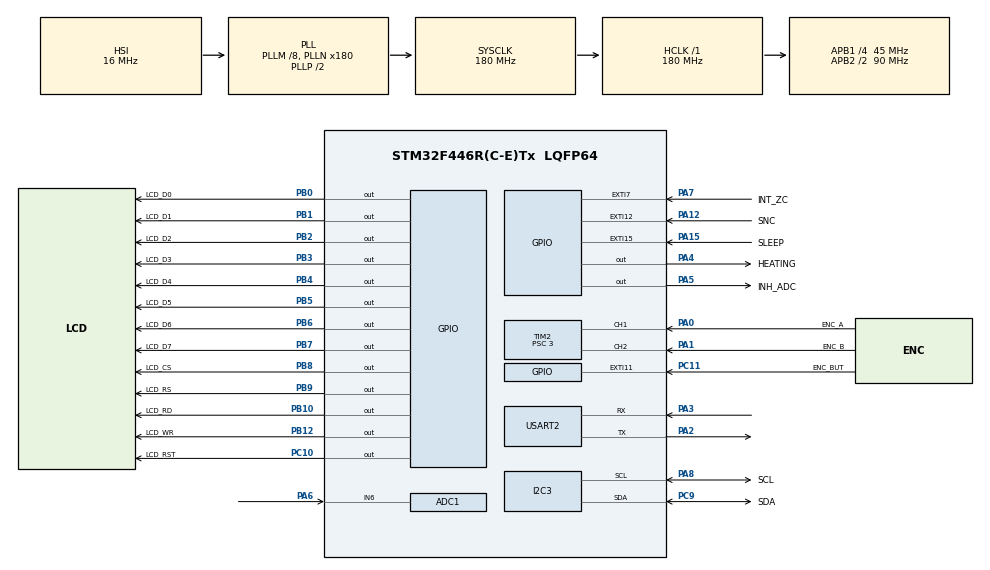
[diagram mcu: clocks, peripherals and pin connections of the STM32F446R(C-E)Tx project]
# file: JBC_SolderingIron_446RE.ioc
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ADC1.Channel-0\#ChannelRegularConversion=ADC_CHANNEL_6
ADC1.NbrOfConversionFlag=1
ADC1.Rank-0\#ChannelRegularConversion=1
ADC1.SamplingTime-0\#ChannelRegularConversion=ADC_SAMPLETIME_3CYCLES
ADC1.master=1
Mcu.Family=STM32F4
Mcu.Name=STM32F446R(C-E)Tx
Mcu.Package=LQFP64
NVIC.ADC_IRQn=true\:0\:0\:false\:false\:true\:true\:true
NVIC.EXTI15_10_IRQn=true\:0\:0\:false\:false\:true\:true\:true
NVIC.EXTI9_5_IRQn=true\:0\:0\:false\:false\:true\:true\:true
NVIC.I2C3_ER_IRQn=true\:0\:0\:false\:false\:true\:true\:true
NVIC.I2C3_EV_IRQn=true\:0\:0\:false\:false\:true\:true\:true
NVIC.PriorityGroup=NVIC_PRIORITYGROUP_4
NVIC.TIM2_IRQn=true\:0\:0\:false\:false\:true\:true\:true
NVIC.USART2_IRQn=true\:0\:0\:false\:false\:true\:true\:true
PA0-WKUP.GPIO_Label=ENC_A
PA0-WKUP.Signal=S_TIM2_CH1_ETR
PA1.GPIO_Label=ENC_B
PA1.Signal=S_TIM2_CH2
PA12.GPIO_Label=SNC
PA12.Signal=GPXTI12
PA13.GPIO_Label=SWDIO
PA13.Mode=Serial_Wire
PA13.Signal=SYS_JTMS-SWDIO
PA14.GPIO_Label=SWDCLK
PA14.Mode=Serial_Wire
PA14.Signal=SYS_JTCK-SWCLK
PA15.GPIO_Label=SLEEP
PA15.Signal=GPXTI15
PA2.Mode=Asynchronous
PA2.Signal=USART2_TX
PA3.Mode=Asynchronous
PA3.Signal=USART2_RX
PA4.GPIO_Label=HEATING
PA4.Signal=GPIO_Output
PA5.GPIO_Label=INH_ADC
PA5.Signal=GPIO_Output
PA6.Signal=ADCx_IN6
PA7.GPIO_Label=INT_ZC
PA7.Signal=GPXTI7
PA8.GPIO_Label=SCL
PA8.Mode=I2C
PA8.Signal=I2C3_SCL
PB0.GPIO_Label=LCD_D0
PB0.Signal=GPIO_Output
PB1.GPIO_Label=LCD_D1
PB1.Signal=GPIO_Output
PB10.GPIO_Label=LCD_RD
PB10.Signal=GPIO_Output
PB12.GPIO_Label=LCD_WR
PB12.Signal=GPIO_Output
PB2.GPIO_Label=LCD_D2
PB2.Signal=GPIO_Output
PB3.GPIO_Label=LCD_D3
PB3.Signal=GPIO_Output
PB4.GPIO_Label=LCD_D4
PB4.Signal=GPIO_Output
PB5.GPIO_Label=LCD_D5
PB5.Signal=GPIO_Output
PB6.GPIO_Label=LCD_D6
PB6.Signal=GPIO_Output
PB7.GPIO_Label=LCD_D7
PB7.Signal=GPIO_Output
PB8.GPIO_Label=LCD_CS
PB8.Signal=GPIO_Output
PB9.GPIO_Label=LCD_RS
PB9.Signal=GPIO_Output
PC10.GPIO_Label=LCD_RST
PC10.Signal=GPIO_Output
PC11.GPIO_Label=ENC_BUT
PC11.Signal=GPXTI11
PC9.GPIO_Label=SDA
PC9.Mode=I2C
PC9.Signal=I2C3_SDA
ProjectManager.HeapSize=0x200
ProjectManager.StackSize=0x400
ProjectManager.TargetToolchain=STM32CubeIDE
RCC.AHBFreq_Value=180000000
RCC.APB1CLKDivider=RCC_HCLK_DIV4
RCC.APB1Freq_Value=45000000
RCC.APB1TimFreq_Value=90000000
RCC.APB2CLKDivider=RCC_HCLK_DIV2
RCC.APB2Freq_Value=90000000
RCC.APB2TimFreq_Value=180000000
RCC.CortexFreq_Value=180000000
RCC.HCLKFreq_Value=180000000
RCC.PLLM=8
RCC.PLLN=180
RCC.SYSCLKFreq_VALUE=180000000
RCC.SYSCLKSource=RCC_SYSCLKSOURCE_PLLCLK
RCC.USBFreq_Value=180000000
RCC.VCOOutputFreq_Value=360000000
SH.ADCx_IN6.0=ADC1_IN6,IN6
SH.S_TIM2_CH1_ETR.0=TIM2_CH1,Encoder_Interface
SH.S_TIM2_CH2.0=TIM2_CH2,Encoder_Interface
TIM2.ClockDivision=TIM_CLOCKDIVISION_DIV4
TIM2.EncoderMode=TIM_ENCODERMODE_TI12
TIM2.IC1Filter=0xF
TIM2.IC1Polarity=TIM_ICPOLARITY_FALLING
TIM2.IC1Prescaler=TIM_ICPSC_DIV8
TIM2.IC2Filter=0xF
TIM2.IC2Polarity=TIM_ICPOLARITY_FALLING
TIM2.IC2Prescaler=TIM_ICPSC_DIV8
TIM2.Period=0xFFFF
TIM2.Prescaler=3
TIM2.TIM_MasterSlaveMode=TIM_MASTERSLAVEMODE_DISABLE
USART2.VirtualMode=VM_ASYNC
VP_CRC_VS_CRC.Mode=CRC_Activate
board=custom

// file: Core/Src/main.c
/* USER CODE BEGIN Header */
/**
  ******************************************************************************
  * @file           : main.c
  * @brief          : Main program body
  ******************************************************************************
  * @attention
  *
  * <h2><center>&copy; Copyright (c) 2019 STMicroelectronics.
  * All rights reserved.</center></h2>
  *
  * This software component is licensed by ST under BSD 3-Clause license,
  * the "License"; You may not use this file except in compliance with the
  * License. You may obtain a copy of the License at:
  *                        opensource.org/licenses/BSD-3-Clause
  *
  ******************************************************************************
  */
/* USER CODE END Header */

#include "main.h"
#include "adc.h"
#include "crc.h"
#include "i2c.h"
#include "tim.h"
#include "usart.h"
#include "gpio.h"

/* USER CODE BEGIN Includes */
#include "Application.h"
/* USER CODE END Includes */

void SystemClock_Config(void);

int main(void)
{

  /* MCU Configuration--------------------------------------------------------*/

  /* Reset of all peripherals, Initializes the Flash interface and the Systick. */
  HAL_Init();

  /* Configure the system clock */
  SystemClock_Config();

  /* Initialize all configured peripherals */
  MX_GPIO_Init();
  MX_ADC1_Init();
  MX_CRC_Init();
  MX_I2C3_Init();
  MX_TIM2_Init();
  MX_USART2_UART_Init();
  /* USER CODE BEGIN 2 */
  MainInit();
  MainTask();
  /* USER CODE END 2 */

  /* Infinite loop */
  while (1)
  {

  }
}

void SystemClock_Config(void)
{
  RCC_OscInitTypeDef RCC_OscInitStruct = {0};
  RCC_ClkInitTypeDef RCC_ClkInitStruct = {0};

  /** Configure the main internal regulator output voltage
  */
  __HAL_RCC_PWR_CLK_ENABLE();
  __HAL_PWR_VOLTAGESCALING_CONFIG(PWR_REGULATOR_VOLTAGE_SCALE1);
  /** Initializes the CPU, AHB and APB busses clocks
  */
  RCC_OscInitStruct.OscillatorType = RCC_OSCILLATORTYPE_HSI;
  RCC_OscInitStruct.HSIState = RCC_HSI_ON;
  RCC_OscInitStruct.HSICalibrationValue = RCC_HSICALIBRATION_DEFAULT;
  RCC_OscInitStruct.PLL.PLLState = RCC_PLL_ON;
  RCC_OscInitStruct.PLL.PLLSource = RCC_PLLSOURCE_HSI;
  RCC_OscInitStruct.PLL.PLLM = 8;
  RCC_OscInitStruct.PLL.PLLN = 180;
  RCC_OscInitStruct.PLL.PLLP = RCC_PLLP_DIV2;
  RCC_OscInitStruct.PLL.PLLQ = 2;
  RCC_OscInitStruct.PLL.PLLR = 2;
  if (HAL_RCC_OscConfig(&RCC_OscInitStruct) != HAL_OK)
  {
    Error_Handler();
  }
  /** Activate the Over-Drive mode
  */
  if (HAL_PWREx_EnableOverDrive() != HAL_OK)
  {
    Error_Handler();
  }
  /** Initializes the CPU, AHB and APB busses clocks
  */
  RCC_ClkInitStruct.ClockType = RCC_CLOCKTYPE_HCLK|RCC_CLOCKTYPE_SYSCLK
                              |RCC_CLOCKTYPE_PCLK1|RCC_CLOCKTYPE_PCLK2;
  RCC_ClkInitStruct.SYSCLKSource = RCC_SYSCLKSOURCE_PLLCLK;
  RCC_ClkInitStruct.AHBCLKDivider = RCC_SYSCLK_DIV1;
  RCC_ClkInitStruct.APB1CLKDivider = RCC_HCLK_DIV4;
  RCC_ClkInitStruct.APB2CLKDivider = RCC_HCLK_DIV2;

  if (HAL_RCC_ClockConfig(&RCC_ClkInitStruct, FLASH_LATENCY_5) != HAL_OK)
  {
    Error_Handler();
  }
}

void Error_Handler(void)
{
}

/************************ (C) COPYRIGHT STMicroelectronics *****END OF FILE****/
